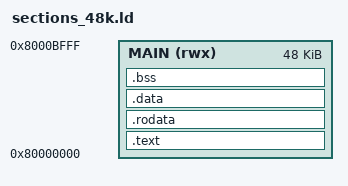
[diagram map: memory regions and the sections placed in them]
/*
 * Combined-image memory contract.
 *
 * The CPU local RAM occupies 48 KiB beginning at 0x80000000.  start.S uses
 * _stack_top, _sbss and _ebss; build_coremark_nes.py consumes _image_end and
 * _stack_limit to prove that code, data and BSS leave the reserved 8 KiB stack
 * untouched.  These symbol names are therefore firmware ABI, not cosmetic.
 */
OUTPUT_ARCH(riscv)
ENTRY(_start)

STACK_SIZE = 8K;
MEMORY { MAIN (rwx) : ORIGIN = 0x80000000, LENGTH = 48K }

SECTIONS {
  .text : {
    KEEP(*(.text.start))
    *(.text*)
  } > MAIN

  .rodata : {
    *(.rodata*)
    *(.srodata*)
  } > MAIN

  .data : {
    . = ALIGN(4);
    *(.data*)
    *(.sdata*)
  } > MAIN

  /* Keep small-data accesses generated by GCC within the GP-relative window. */
  PROVIDE(__global_pointer$ = ADDR(.data) + 0x800);

  .bss (NOLOAD) : {
    . = ALIGN(4);
    _sbss = .;
    *(.bss*)
    *(.sbss*)
    *(COMMON)
    . = ALIGN(4);
    _ebss = .;
  } > MAIN

  . = ALIGN(16);
  _image_end = .;
  _stack_top = ORIGIN(MAIN) + LENGTH(MAIN);
  _stack_limit = _stack_top - STACK_SIZE;

  /* A link failure is safer than overwriting the runtime stack at boot. */
  ASSERT(_image_end <= _stack_limit,
         "Combined CoreMark/NES image leaves less than 8 KiB for the runtime stack")
}
